# AVR128DB28 register map
Vendor: Atmel; File version: 1.0
CPU: other r0p0, little endian, no MPU, no FPU, 4 interrupt priority bits
Registers are 8-bit, read-write, reset 0x0 unless marked. A register's access mark holds for its fields unless they carry their own. Offsets are from the block's base; [hi:lo] are bit positions; {n}, {i} and the like mark numbered series; 'fields as' and 'values as' point back to an identical list.

## OPAMP — Operational Amplifier System
Base 0x00800700
0x00 CTRLA — Control A
  [0] ENABLE — Op Amp System Enable
0x01 DBGCTRL — Debug Control
  [0] DBGRUN — Run in Debug Mode
0x02 TIMEBASE — Timebase Value
  [6:0] TIMEBASE
0x0F PWRCTRL — Power Control
  [0] IRSEL — Input Range Select
    0=FULL (Full Input Range); 1=REDUCED (Reduced Input Range)
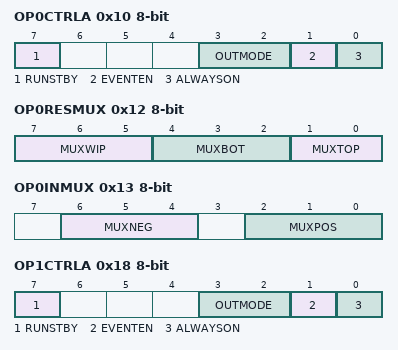
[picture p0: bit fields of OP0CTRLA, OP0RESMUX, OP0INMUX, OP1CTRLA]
0x10 OP0CTRLA — Op Amp 0 Control A
  [7] RUNSTBY — Run in Standby Mode
  [3:2] OUTMODE — Output Mode
    0=OFF (Output Driver Off); 1=NORMAL (Output Driver in Normal Mode)
  [1] EVENTEN — Enable Events
  [0] ALWAYSON
0x11 OP0STATUS — Op Amp 0 Status
  [0] SETTLED ro
0x12 OP0RESMUX — Op Amp 0 Resistor Ladder Multiplexer
  [7:5] MUXWIP — Multiplexer Wiper selector
    0=WIP0 (R1 = 15R, R2 = 1R, R2/R1 = 0.07); 1=WIP1 (R1 = 14R, R2 = 2R, R2/R1 = 0.14); 2=WIP2 (R1 = 12R, R2 = 4R, R2/R1 = 0.33); 3=WIP3 (R1 = 8R, R2 = 8R, R2/R1 = 1); 4=WIP4 (R1 = 6R, R2 = 10R, R2/R1 = 1.67); 5=WIP5 (R1 = 4R, R2 = 12R, R2/R1 = 3); 6=WIP6 (R1 = 2R, R2 = 14R, R2/R1 = 7); 7=WIP7 (R1 = 1R, R2 = 15R, R2/R1 = 15)
  [4:2] MUXBOT — Multiplexer Bottom
    0=OFF (Multiplexer off); 1=INP (Positive input pin for OPn); 2=INN (Negative input pin for OPn); 3=DAC (DAC output); 4=LINKOUT (Link OP[n-1] output); 5=GND (Ground)
  [1:0] MUXTOP — Multiplexer Top
    0=OFF (Multiplexer off); 1=OUT (OPn output); 2=VDD
0x13 OP0INMUX — Op Amp 0 Input Multiplexer
  [6:4] MUXNEG — Negative Input Multiplexer
    0=INN (Negative input pin for OPn); 1=WIP (Wiper from OPn's resistor ladder); 2=OUT (OPn output (unity gain)); 3=DAC (DAC output)
  [2:0] MUXPOS — Positive Input Multiplexer
    0=INP (Positive input pin for OPn); 1=WIP (Wiper from OPn's resistor ladder); 2=DAC (DAC output); 3=GND (Ground); 4=VDDDIV2 (VDD/2)
0x14 OP0SETTLE — Op Amp 0 Settle
  [6:0] SETTLE — Settle Time
0x15 OP0CAL — Op Amp 0 Calibration
  [7:0] CAL — Calibration (for input offset voltage)
0x18 OP1CTRLA — Op Amp 1 Control A
  fields as OP0CTRLA
0x19 OP1STATUS — Op Amp 1 Status
  [0] SETTLED ro
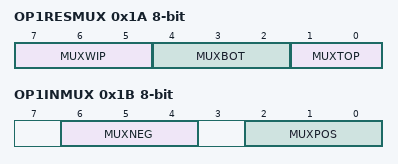
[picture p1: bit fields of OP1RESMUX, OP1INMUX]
0x1A OP1RESMUX — Op Amp 1 Resistor Ladder Multiplexer
  fields as OP0RESMUX
0x1B OP1INMUX — Op Amp 1 Input Multiplexer
  [6:4] MUXNEG — Negative Input Multiplexer
    values as OP0INMUX.MUXNEG
  [2:0] MUXPOS — Positive Input Multiplexer
    0=INP (Positive input pin for OPn); 1=WIP (Wiper from OPn's resistor ladder); 2=DAC (DAC output); 3=GND (Ground); 4=VDDDIV2 (VDD/2); 5=LINKOUT (Output from OP0)
0x1C OP1SETTLE — Op Amp 1 Settle
  [6:0] SETTLE — Settle Time
0x1D OP1CAL — Op Amp 1 Calibration
  [7:0] CAL — Calibration (for input offset voltage)

## PORTA — I/O Ports
Base 0x00800400
Same registers: PORTD 0x00800460, PORTF 0x008004A0
0x00 DIR — Data Direction
0x01 DIRSET — Data Direction Set
0x02 DIRCLR — Data Direction Clear
0x03 DIRTGL — Data Direction Toggle
0x04 OUT — Output Value
0x05 OUTSET — Output Value Set
0x06 OUTCLR — Output Value Clear
0x07 OUTTGL — Output Value Toggle
0x08 IN — Input Value
0x09 INTFLAGS — Interrupt Flags
  [7:0] INT — Pin Interrupt Flag
0x0A PORTCTRL — Port Control
  [0] SRL — Slew Rate Limit Enable
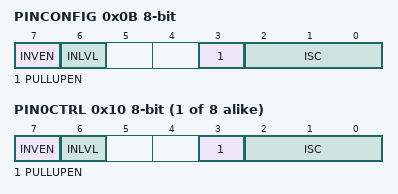
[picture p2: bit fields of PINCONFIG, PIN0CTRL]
0x0B PINCONFIG — Pin Control Config
  [7] INVEN — Inverted I/O Enable
  [6] INLVL — Input level select
  [3] PULLUPEN — Pullup enable
  [2:0] ISC — Input/Sense Configuration
    0=INTDISABLE (Interrupt disabled but input buffer enabled); 1=BOTHEDGES (Sense Both Edges); 2=RISING (Sense Rising Edge); 3=FALLING (Sense Falling Edge); 4=INPUT_DISABLE (Digital Input Buffer disabled); 5=LEVEL (Sense low Level)
0x0C PINCTRLUPD — Pin Control Update
  [7:0] PINCTRLUPD — Pin control update mask
0x0D PINCTRLSET — Pin Control Set
  [7:0] PINCTRLSET — Pin control set mask
0x0E PINCTRLCLR — Pin Control Clear
  [7:0] PINCTRLCLR — Pin control clear mask
{0x10+i} PIN{i}CTRL (i=0..7) — Pin {i} Control
  fields as PINCONFIG

## PORTC — I/O Ports
Base 0x00800440
Registers as PORTA, without PORTCTRL; these are added or differ:
0x0A PORTCTRL — Port Control
  [0] SRL — Slew Rate Limit Enable
